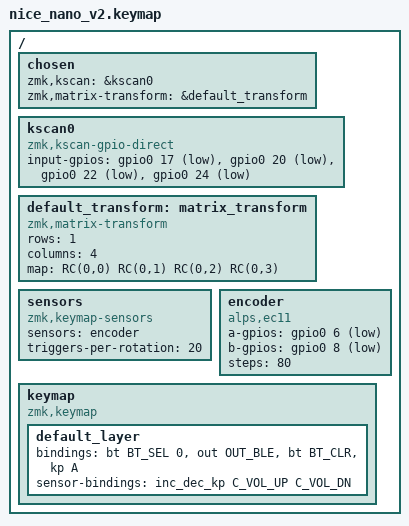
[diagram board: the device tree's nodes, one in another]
#include <behaviors.dtsi>
#include <dt-bindings/zmk/bt.h>
#include <dt-bindings/zmk/keys.h>
#include <dt-bindings/zmk/matrix_transform.h>
#include <dt-bindings/zmk/outputs.h>

/ {
    chosen {
        zmk,kscan = &kscan0;
        zmk,matrix-transform = &default_transform;
    };

    kscan0: kscan0 {
        compatible = "zmk,kscan-gpio-direct";
        input-gpios =
            <&gpio0 17 (GPIO_ACTIVE_LOW | GPIO_PULL_UP)>,
            <&gpio0 20 (GPIO_ACTIVE_LOW | GPIO_PULL_UP)>,
            <&gpio0 22 (GPIO_ACTIVE_LOW | GPIO_PULL_UP)>,
            <&gpio0 24 (GPIO_ACTIVE_LOW | GPIO_PULL_UP)>;
    };

    default_transform: matrix_transform {
        compatible = "zmk,matrix-transform";
        rows = <1>;
        columns = <4>;
        map = <RC(0,0) RC(0,1) RC(0,2) RC(0,3)>;
    };

    sensors: sensors {
        compatible = "zmk,keymap-sensors";
        sensors = <&encoder>;
        triggers-per-rotation = <20>;
    };

    encoder: encoder {
        compatible = "alps,ec11";
        a-gpios = <&gpio0 6 (GPIO_ACTIVE_LOW | GPIO_PULL_UP)>;
        b-gpios = <&gpio0 8 (GPIO_ACTIVE_LOW | GPIO_PULL_UP)>;
        steps = <80>;
    };

    keymap {
        compatible = "zmk,keymap";

        default_layer {
            bindings = <&bt BT_SEL 0 &out OUT_BLE &bt BT_CLR &kp A>;
            sensor-bindings = <&inc_dec_kp C_VOL_UP C_VOL_DN>;
        };
    };
};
